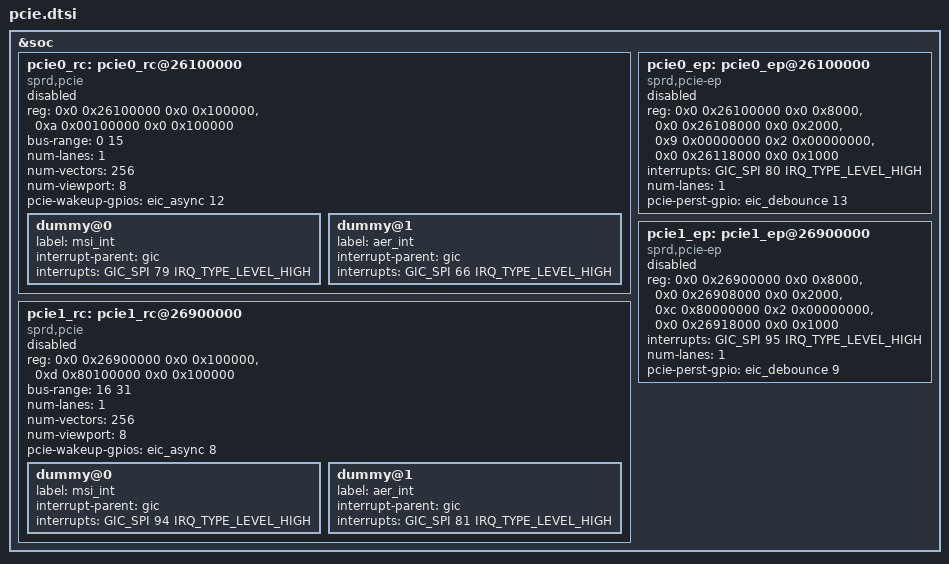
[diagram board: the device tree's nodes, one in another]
// SPDX-License-Identifier: (GPL-2.0+ OR MIT)
/*
 * Unisoc PCIe dts file
 *
 * Copyright (C) 2020, Unisoc Inc.
 *
 */
&soc {
	pcie0_rc: pcie0_rc@26100000 {
		compatible = "sprd,pcie", "snps,dw-pcie";
		reg = <0x0 0x26100000 0x0 0x100000>,
		      <0xa 0x00100000 0x0 0x100000>;
		reg-names = "dbi", "config";
		#address-cells = <3>;
		#size-cells = <2>;
		device_type = "pci";
		ranges = <0x01000000 0x1 0x00000000 0xa 0x00000000 0x0 0x00010000
			  0x03000000 0x0 0x00000000 0x9 0x00000000 0x0 0xffffffff>;
		bus-range = <0 15>;
		num-lanes = <1>;
		num-vectors = <256>;
		num-viewport = <8>;
		pcie-wakeup-gpios = <&eic_async 12 GPIO_ACTIVE_HIGH>;
		status = "disabled";
		dummy@0 {
			label = "msi_int";
			interrupt-parent = <&gic>;
			#interrupt-cells = <3>;
			interrupts = <GIC_SPI 79
				      IRQ_TYPE_LEVEL_HIGH>;
		};
		dummy@1 {
			label = "aer_int";
			interrupt-parent = <&gic>;
			#interrupt-cells = <3>;
			interrupts = <GIC_SPI 66
				      IRQ_TYPE_LEVEL_HIGH>;
		};
	};

	pcie0_ep: pcie0_ep@26100000 {
		compatible = "sprd,pcie-ep", "snps,dw-pcie";
		reg = <0x0 0x26100000 0x0 0x8000>,
		      <0x0 0x26108000 0x0 0x2000>,
		      <0x9 0x00000000 0x2 0x00000000>,
		      <0x0 0x26118000 0x0 0x1000>;
		reg-names = "dbi", "dbi2","addr_space","atu";
		interrupts = <GIC_SPI 80 IRQ_TYPE_LEVEL_HIGH>;
		num-lanes = <1>;
		pcie-perst-gpio = <&eic_debounce 13 GPIO_ACTIVE_HIGH>;
		status = "disabled";
	};

	pcie1_rc: pcie1_rc@26900000 {
		compatible = "sprd,pcie", "snps,dw-pcie";
		reg = <0x0 0x26900000 0x0 0x100000>,
		      <0xd 0x80100000 0x0 0x100000>;
		reg-names = "dbi", "config";
		#address-cells = <3>;
		#size-cells = <2>;
		device_type = "pci";
		ranges = <0x01000000 0x1 0x00000000 0xd 0x80000000 0x0 0x00010000
			  0x03000000 0x0 0x00000000 0xc 0x80000000 0x0 0xffffffff>;
		bus-range = <16 31>;
		num-lanes = <1>;
		num-vectors = <256>;
		num-viewport = <8>;
		pcie-wakeup-gpios = <&eic_async 8 GPIO_ACTIVE_HIGH>;
		status = "disabled";
		dummy@0 {
			label = "msi_int";
			interrupt-parent = <&gic>;
			#interrupt-cells = <3>;
			interrupts = <GIC_SPI 94
				      IRQ_TYPE_LEVEL_HIGH>;
		};
		dummy@1 {
			label = "aer_int";
			interrupt-parent = <&gic>;
			#interrupt-cells = <3>;
			interrupts = <GIC_SPI 81
				      IRQ_TYPE_LEVEL_HIGH>;
		};
	};

	pcie1_ep: pcie1_ep@26900000 {
		compatible = "sprd,pcie-ep", "snps,dw-pcie";
		reg = <0x0 0x26900000 0x0 0x8000>,
		      <0x0 0x26908000 0x0 0x2000>,
		      <0xc 0x80000000 0x2 0x00000000>,
		      <0x0 0x26918000 0x0 0x1000>;
		reg-names = "dbi", "dbi2","addr_space","atu";
		interrupts = <GIC_SPI 95 IRQ_TYPE_LEVEL_HIGH>;
		num-lanes = <1>;
		pcie-perst-gpio = <&eic_debounce 9 GPIO_ACTIVE_HIGH>;
		status = "disabled";
	};
};
